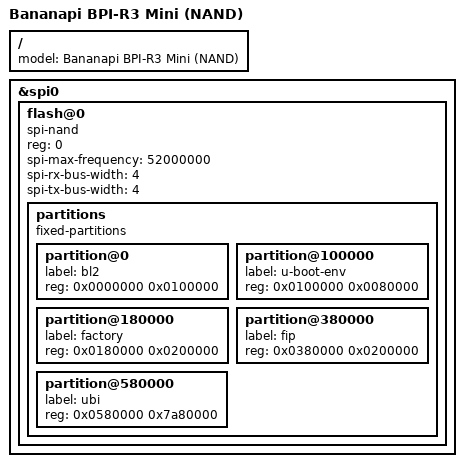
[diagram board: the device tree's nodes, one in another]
// SPDX-License-Identifier: GPL-2.0-or-later OR MIT

/dts-v1/;
#include "mt7986a-bananapi-bpi-r3-mini.dts"

/ {
	model = "Bananapi BPI-R3 Mini (NAND)";
};

&spi0 {
	flash@0 {
		compatible = "spi-nand";
		#address-cells = <1>;
		#size-cells = <1>;
		reg = <0>;

		spi-max-frequency = <52000000>;
		spi-rx-bus-width = <4>;
		spi-tx-bus-width = <4>;

		partitions {
			compatible = "fixed-partitions";
			#address-cells = <1>;
			#size-cells = <1>;

			partition@0 {
				label = "bl2";
				reg = <0x0000000 0x0100000>;
			};

			partition@100000 {
				label = "u-boot-env";
				reg = <0x0100000 0x0080000>;
			};

			partition@180000 {
				label = "factory";
				reg = <0x0180000 0x0200000>;
			};

			partition@380000 {
				label = "fip";
				reg = <0x0380000 0x0200000>;
			};

			partition@580000 {
				label = "ubi";
				reg = <0x0580000 0x7a80000>;
			};
		};
	};
};
